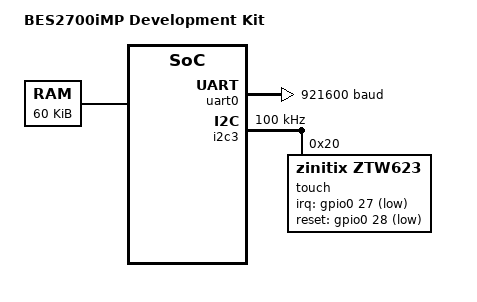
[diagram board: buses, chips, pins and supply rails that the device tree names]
/*
 * SPDX-FileCopyrightText: Copyright The Zephyr Project Contributors
 * SPDX-License-Identifier: Apache-2.0
 */

/dts-v1/;

#include <bestechnic/bes2700imp.dtsi>
#include <zephyr/dt-bindings/gpio/gpio.h>

/ {
	model = "BES2700iMP Development Kit";
	compatible = "bestechnic,bes2700imp-devkit";

	chosen {
		zephyr,console = &uart0;
		zephyr,sram = &sram0;
	};

	sram0: memory@20070000 {
		compatible = "mmio-sram";
		reg = <0x20070000 DT_SIZE_K(60)>;
	};
};

&uart0 {
	current-speed = <921600>;
	status = "okay";
};

&gpio0 {
	ngpios = <29>;
	gpio-reserved-ranges = <0 27>;
	status = "okay";
};

&i2c3 {
	clock-frequency = <100000>;
	hcnt-offset = <8>;
	lcnt-offset = <8>;
	i2c-sda-hold-time-ns = <1800>;
	status = "okay";

	touch: touch@20 {
		compatible = "zinitix,ztw623";
		reg = <0x20>;
		irq-gpios = <&gpio0 27 GPIO_ACTIVE_LOW>;
		reset-gpios = <&gpio0 28 GPIO_ACTIVE_LOW>;
		screen-width = <212>;
		screen-height = <520>;
	};
};

&{/soc} {
	panel: display@40089000 {
		compatible = "bestechnic,bes2700imp-devkit-panel";
		reg = <0x40089000 0x54>, <0x40086080 0x4>,
		      <0x40081000 0x54>, <0x40086010 0x4>,
		      <0x40200000 0x300>, <0x20035d40 0x35d80>;
		reg-names = "gpio", "mux", "reset_gpio", "reset_mux", "lcdc", "lcdc_buffer";
		width = <212>;
		height = <520>;
		row-offset = <14>;
		clock-pin = <8>;
		cs-pin = <9>;
		data-pin-start = <10>;
		reset-pin = <24>;
		status = "disabled";
	};
};
